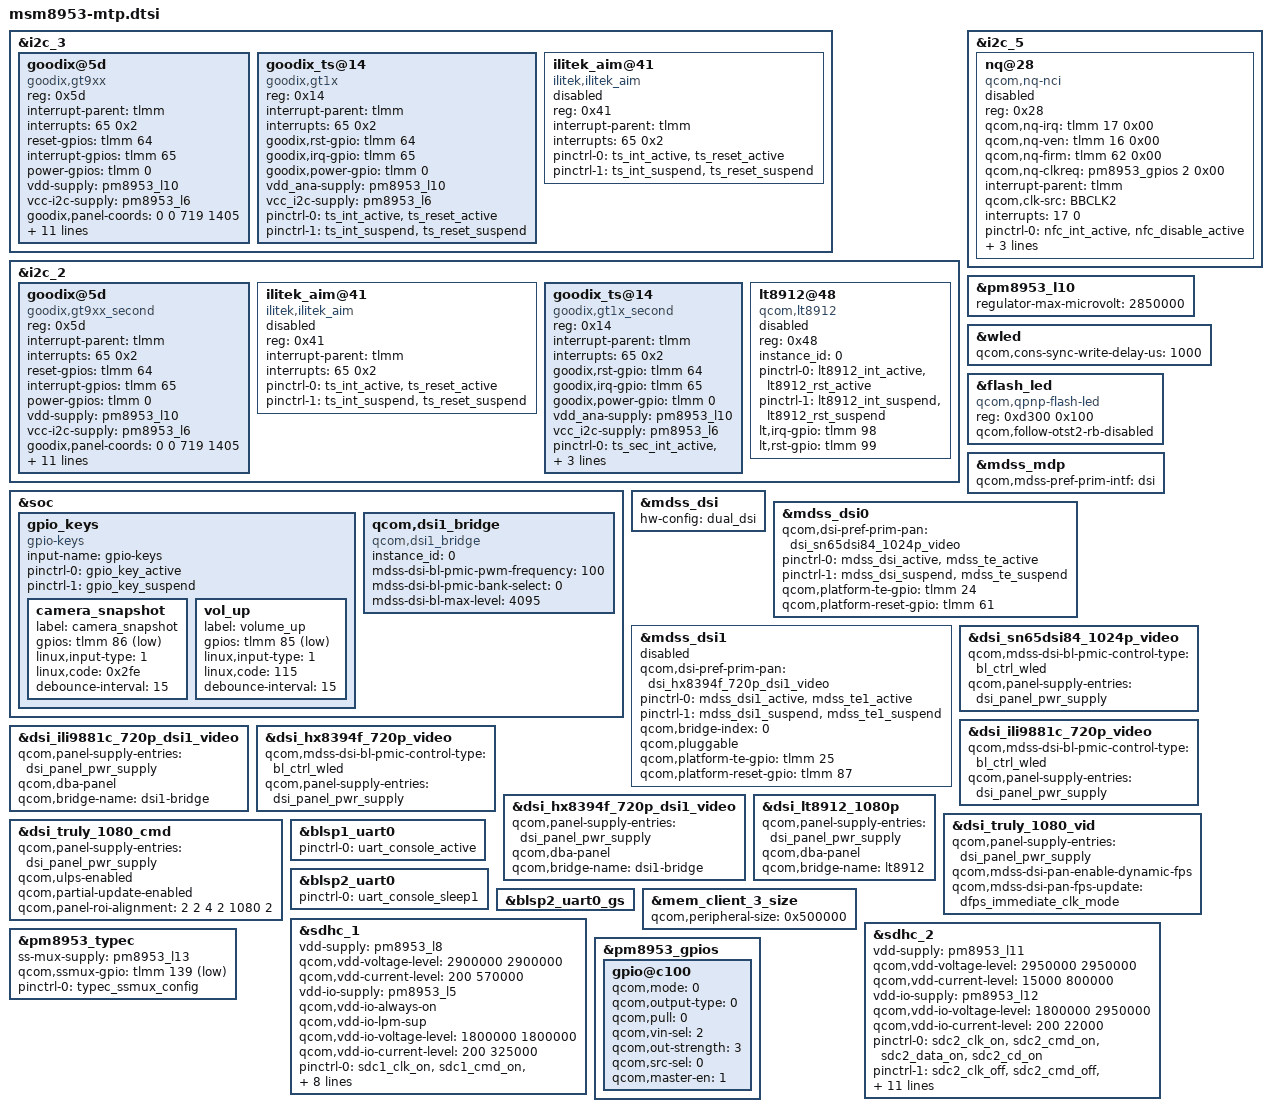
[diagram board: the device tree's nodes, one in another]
/*
 * Copyright (c) 2015-2017, The Linux Foundation. All rights reserved.
 *
 * This program is free software; you can redistribute it and/or modify
 * it under the terms of the GNU General Public License version 2 and
 * only version 2 as published by the Free Software Foundation.
 *
 * This program is distributed in the hope that it will be useful,
 * but WITHOUT ANY WARRANTY; without even the implied warranty of
 * MERCHANTABILITY or FITNESS FOR A PARTICULAR PURPOSE.  See the
 * GNU General Public License for more details.
 */

#include "msm8953-pinctrl.dtsi"
#include "msm8953-audio-mtp.dtsi"
//barnett-> del spi3
//&spi_3 { /* BLSP1 QUP3 */
/*	spi-max-frequency = <16000000>;
	maxim_sti@0 {
		status = "disabled";
		compatible = "maxim,maxim_sti";
		reg = <0>;
		interrupt-parent = <&tlmm>;
		interrupts = <65 0>;
		spi-max-frequency = <16000000>;
		avdd-supply = <&pm8953_l10>;
		dvdd-supply = <&pm8953_l5>;
		maxim_sti,irq-gpio = <&tlmm 65 0x00>;
		maxim_sti,reset-gpio = <&tlmm 64 0x00>;
		maxim_sti,touch_fusion = "/vendor/bin/touch_fusion";
		maxim_sti,config_file = "/etc/firmware/qtc800s.cfg";
		maxim_sti,fw_name = "qtc800s.bin";
		pinctrl-names = "pmx_ts_active","pmx_ts_suspend",
						"pmx_ts_release";
		pinctrl-0 = <&ts_int_active &ts_reset_active>;
		pinctrl-1 = <&ts_int_suspend &ts_reset_suspend>;
		pinctrl-2 = <&ts_release>;
	};
};
->barnett */

//barnett-> add i2c3 and gt9xx
&i2c_3 {  /* BLSP1 QUP3 */ 
    status = "ok";
    goodix@5d {
        compatible = "goodix,gt9xx";
        reg = <0x5d>;
        interrupt-parent = <&tlmm>;
        interrupts = <65 0x2>;
        reset-gpios = <&tlmm 64 0x0>;
        interrupt-gpios = <&tlmm 65 0x2008>;
        power-gpios = <&tlmm 0 0x0>;
        vdd-supply = <&pm8953_l10>;
        vcc-i2c-supply = <&pm8953_l6>;
        goodix,panel-coords = <0 0 719 1405>;
        goodix,display-coords = <0 0 719 1279>;
        goodix,button-map= <139 172 158>;
        goodix,enable-power-off;
        goodix,product-id = "9147";
        goodix,fw_name = "gtp_fw.bin";
        pinctrl-names = "pmx_ts_active","pmx_ts_suspend";
        pinctrl-0 = <&ts_int_active &ts_reset_active>;
        pinctrl-1 = <&ts_int_suspend &ts_reset_suspend>;
        goodix,cfg-data0 = [
        44 DA 02 05 05 05 35 C1 01 09
        28 08 48 35 03 05 00 00 FF 7F
        10 50 85 14 17 1A 14 92 00 0A
        31 2F D3 07 03 00 00 A2 33 1D
        00 01 00 00 00 1E 00 09 10 00
        2A 1E 50 94 C5 02 00 0E 00 04
        B1 21 00 96 28 00 7F 31 00 6F
        3B 00 60 48 00 60 10 30 48 00
        F0 4A 3A FF EF 27 00 00 00 00
        00 01 1C 19 17 0F 01 00 01 0F
        0F 03 04 10 42 8F 0F 19 00 00
        46 37 08 0A 0C 0E 10 12 14 16
        18 1A 00 00 00 00 00 00 00 00
        00 00 00 00 00 00 00 00 00 00
        00 00 08 20 0A 1F 0C 1E 0E 1D
        22 05 24 04 28 00 29 02 2A 06
        00 00 00 00 00 00 00 00 00 00
        00 FF FF FF FF FF FF FF FF AF
        FF FF FF FF 87 01
        ];
        goodix,have-touch-key;
        goodix,driver-send-cfg;
    };

    goodix_ts@14 {
		compatible = "goodix,gt1x";
		reg = <0x14>;
		interrupt-parent = <&tlmm>;
		interrupts = <65 0x2>;
		goodix,rst-gpio  = <&tlmm 64 0x0>;
		goodix,irq-gpio = <&tlmm 65 0x2008>;
		goodix,power-gpio = <&tlmm 0 0x0>;
		vdd_ana-supply = <&pm8953_l10>;
		vcc_i2c-supply  = <&pm8953_l6>;
		pinctrl-names = "pmx_ts_active","pmx_ts_suspend";
		pinctrl-0 = <&ts_int_active &ts_reset_active>;
		pinctrl-1 = <&ts_int_suspend &ts_reset_suspend>;
	};

	ilitek_aim@41 {
		compatible = "ilitek,ilitek_aim";
		reg = <0x41>;
		interrupt-parent = <&tlmm>;
		interrupts = <65 0x2>;
		pinctrl-names = "pmx_ts_active","pmx_ts_suspend";
		pinctrl-0 = <&ts_int_active &ts_reset_active>;
		pinctrl-1 = <&ts_int_suspend &ts_reset_suspend>;
		status = "disabled";
	};
};
//->barnett
//barnett-> add second tp
&i2c_2 {
    goodix@5d {
        compatible = "goodix,gt9xx_second";
        reg = <0x5d>;
        interrupt-parent = <&tlmm>;
        interrupts = <65 0x2>;
        reset-gpios = <&tlmm 64 0x0>;
        interrupt-gpios = <&tlmm 65 0x2008>;
        power-gpios = <&tlmm 0 0x0>;
        vdd-supply = <&pm8953_l10>;
        vcc-i2c-supply = <&pm8953_l6>;
        goodix,panel-coords = <0 0 719 1405>;
        goodix,display-coords = <0 0 719 1279>;
        goodix,button-map= <139 172 158>;
        goodix,enable-power-off;
        goodix,product-id = "9147";
        goodix,fw_name = "gtp_fw.bin";
        pinctrl-names = "pmx_ts_sec_active","pmx_ts_sec_suspend";
        pinctrl-0 = <&ts_int_active &ts_reset_active>;
        pinctrl-1 = <&ts_int_suspend &ts_reset_suspend>;
        goodix,cfg-data0 = [
        44 DA 02 05 05 05 35 C1 01 09
        28 08 48 35 03 05 00 00 FF 7F
        10 50 85 14 17 1A 14 92 00 0A
        31 2F D3 07 03 00 00 A2 33 1D
        00 01 00 00 00 1E 00 09 10 00
        2A 1E 50 94 C5 02 00 0E 00 04
        B1 21 00 96 28 00 7F 31 00 6F
        3B 00 60 48 00 60 10 30 48 00
        F0 4A 3A FF EF 27 00 00 00 00
        00 01 1C 19 17 0F 01 00 01 0F
        0F 03 04 10 42 8F 0F 19 00 00
        46 37 08 0A 0C 0E 10 12 14 16
        18 1A 00 00 00 00 00 00 00 00
        00 00 00 00 00 00 00 00 00 00
        00 00 08 20 0A 1F 0C 1E 0E 1D
        22 05 24 04 28 00 29 02 2A 06
        00 00 00 00 00 00 00 00 00 00
        00 FF FF FF FF FF FF FF FF AF
        FF FF FF FF 87 01
        ];
        goodix,have-touch-key;
        goodix,driver-send-cfg;
    };

	ilitek_aim@41 {
		compatible = "ilitek,ilitek_aim";
		reg = <0x41>;
		interrupt-parent = <&tlmm>;
		interrupts = <65 0x2>;
	        pinctrl-names = "pmx_ts_sec_active","pmx_ts_sec_suspend";
        	pinctrl-0 = <&ts_int_active &ts_reset_active>;
            	pinctrl-1 = <&ts_int_suspend &ts_reset_suspend>;
		status = "disabled";
	};

	goodix_ts@14 {
            compatible = "goodix,gt1x_second";
            reg = <0x14>;
            interrupt-parent = <&tlmm>;
            interrupts = <65 0x2>;
            goodix,rst-gpio  = <&tlmm 64 0x0>;
            goodix,irq-gpio = <&tlmm 65 0x2008>;
            goodix,power-gpio = <&tlmm 0 0x0>;
            vdd_ana-supply = <&pm8953_l10>;
            vcc_i2c-supply  = <&pm8953_l6>;
            pinctrl-names = "pmx_ts_sec_active","pmx_ts_sec_suspend";
            pinctrl-0 = <&ts_sec_int_active &ts_sec_reset_active>;
            pinctrl-1 = <&ts_sec_int_suspend &ts_sec_reset_suspend>;
	};
 	
     lt8912@48 {
	status = "disabled";
        compatible = "qcom,lt8912";
        reg = <0x48>;
        instance_id = <0>;
        //lt,enable-audio;
        pinctrl-names = "pmx_lt8912_active",
                       "pmx_lt8912_suspend";
        pinctrl-0 = <&lt8912_int_active &lt8912_rst_active>;
        pinctrl-1 = <&lt8912_int_suspend &lt8912_rst_suspend>;
        lt,irq-gpio = <&tlmm 98 0x2002>;
        lt,rst-gpio = <&tlmm 99 0x2002>;
    };
 };
//->barnett

&i2c_5 { /* BLSP2 QUP1 (NFC) */
	nq@28 {
		compatible = "qcom,nq-nci";
		reg = <0x28>;
		qcom,nq-irq = <&tlmm 17 0x00>;
		qcom,nq-ven = <&tlmm 16 0x00>;
		qcom,nq-firm = <&tlmm 62 0x00>;
		qcom,nq-clkreq = <&pm8953_gpios 2 0x00>;
		interrupt-parent = <&tlmm>;
		qcom,clk-src = "BBCLK2";
		interrupts = <17 0>;
		interrupt-names = "nfc_irq";
		pinctrl-names = "nfc_active", "nfc_suspend";
		pinctrl-0 = <&nfc_int_active &nfc_disable_active>;
		pinctrl-1 = <&nfc_int_suspend &nfc_disable_suspend>;
		clocks = <&clock_gcc clk_bb_clk2_pin>;
		clock-names = "ref_clk";
		status = "disabled";
	};
};

&pm8953_l10 {
	regulator-max-microvolt = <2850000>;
};

&soc {
	gpio_keys {
		compatible = "gpio-keys";
		input-name = "gpio-keys";
		pinctrl-names = "tlmm_gpio_key_active","tlmm_gpio_key_suspend";
		pinctrl-0 = <&gpio_key_active>;
		pinctrl-1 = <&gpio_key_suspend>;

		camera_snapshot {
			label = "camera_snapshot";
			gpios = <&tlmm 86 0x1>;
			linux,input-type = <1>;
			linux,code = <0x2fe>;
			debounce-interval = <15>;
		};

		vol_up {
			label = "volume_up";
			gpios = <&tlmm 85 0x1>;
			linux,input-type = <1>;
			linux,code = <115>;
			debounce-interval = <15>;
		};
	};
/*barnett-> rm improvetouch
	hbtp {
		compatible = "qcom,hbtp-input";
		vcc_ana-supply = <&pm8953_l10>;
		vcc_dig-supply = <&pm8953_l5>;
		qcom,afe-load = <50000>;
		qcom,afe-vtg-min = <2850000>;
		qcom,afe-vtg-max = <2850000>;
		qcom,dig-load = <15000>;
		qcom,dig-vtg-min = <1800000>;
		qcom,dig-vtg-max = <1800000>;
	};
->barnett*/
//barnett:add dsi1 bridge for dual mipi dsi
    qcom,dsi1_bridge {
        compatible = "qcom,dsi1_bridge";
        instance_id = <0>;
        mdss-dsi-bl-pmic-pwm-frequency = <100>;
        mdss-dsi-bl-pmic-bank-select = <0>;
        mdss-dsi-bl-max-level = <4095>;
    };
};
/*
&pmi_haptic{
	qcom,actuator-type = "lra";
	qcom,lra-auto-res-mode="qwd";
	qcom,lra-high-z="opt1";
	qcom,lra-res-cal-period = <0>;
	qcom,wave-play-rate-us = <4165>;
};
*/
&wled {
	qcom,cons-sync-write-delay-us = <1000>;
};

&flash_led {
	compatible = "qcom,qpnp-flash-led";
	reg = <0xd300 0x100>;
	qcom,follow-otst2-rb-disabled;
};

#include "msm8953-mdss-panels.dtsi"

&mdss_mdp {
	qcom,mdss-pref-prim-intf = "dsi";
};

&mdss_dsi {
	hw-config = "dual_dsi"; //"single_dsi";
};

&mdss_dsi0 {
	qcom,dsi-pref-prim-pan = <&dsi_sn65dsi84_1024p_video>;
	pinctrl-names = "mdss_default", "mdss_sleep";
	pinctrl-0 = <&mdss_dsi_active &mdss_te_active>;
	pinctrl-1 = <&mdss_dsi_suspend &mdss_te_suspend>;

	qcom,platform-te-gpio = <&tlmm 24 0>;
	qcom,platform-reset-gpio = <&tlmm 61 0>;
//	qcom,platform-bklight-en-gpio = <&tlmm 59 0>; //not use
};

&mdss_dsi1 {
	status = "disabled";
	qcom,dsi-pref-prim-pan = <&dsi_hx8394f_720p_dsi1_video>;
	pinctrl-names = "mdss_default", "mdss_sleep";
	pinctrl-0 = <&mdss_dsi1_active &mdss_te1_active>;
	pinctrl-1 = <&mdss_dsi1_suspend &mdss_te1_suspend>;

	qcom,bridge-index = <0>;
	qcom,pluggable;
	qcom,platform-te-gpio = <&tlmm 25 0>;
	qcom,platform-reset-gpio = <&tlmm 87 0>;
//	qcom,platform-bklight-en-gpio = <&tlmm 59 0>; //not use
};

&dsi_sn65dsi84_1024p_video {
        qcom,mdss-dsi-bl-pmic-control-type = "bl_ctrl_wled";
        qcom,panel-supply-entries = <&dsi_panel_pwr_supply>;
};

&dsi_ili9881c_720p_video {
	qcom,mdss-dsi-bl-pmic-control-type = "bl_ctrl_wled";
	qcom,panel-supply-entries = <&dsi_panel_pwr_supply>;
	//qcom,mdss-dsi-pan-enable-dynamic-fps;
	//qcom,mdss-dsi-pan-fps-update = "dfps_immediate_porch_mode_vfp";
	//qcom,cont-splash-enabled;
};

/*barnett: backlight control by pwm*/
&dsi_ili9881c_720p_dsi1_video {
    qcom,panel-supply-entries = <&dsi_panel_pwr_supply>;
    //qcom,mdss-dsi-pan-enable-dynamic-fps;
    //qcom,mdss-dsi-pan-fps-update = "dfps_immediate_porch_mode_vfp";
    //qcom,cont-splash-enabled;

    qcom,dba-panel;
    qcom,bridge-name = "dsi1-bridge";
};

&dsi_hx8394f_720p_video {
	qcom,mdss-dsi-bl-pmic-control-type = "bl_ctrl_wled";
	qcom,panel-supply-entries = <&dsi_panel_pwr_supply>;
	//qcom,mdss-dsi-pan-enable-dynamic-fps;
	//qcom,mdss-dsi-pan-fps-update = "dfps_immediate_porch_mode_vfp";
	//qcom,cont-splash-enabled;
};

/*barnett: backlight control by pwm*/
&dsi_hx8394f_720p_dsi1_video {
	qcom,panel-supply-entries = <&dsi_panel_pwr_supply>;
	//qcom,mdss-dsi-pan-enable-dynamic-fps;
	//qcom,mdss-dsi-pan-fps-update = "dfps_immediate_porch_mode_vfp";
	//qcom,cont-splash-enabled;

	qcom,dba-panel;
	qcom,bridge-name = "dsi1-bridge";
};

&dsi_lt8912_1080p {
    qcom,panel-supply-entries = <&dsi_panel_pwr_supply>;
    qcom,dba-panel;
    qcom,bridge-name = "lt8912";
};

&dsi_truly_1080_vid {
	qcom,panel-supply-entries = <&dsi_panel_pwr_supply>;
	qcom,mdss-dsi-pan-enable-dynamic-fps;
	qcom,mdss-dsi-pan-fps-update = "dfps_immediate_clk_mode";
};

&dsi_truly_1080_cmd {
	qcom,panel-supply-entries = <&dsi_panel_pwr_supply>;
	qcom,ulps-enabled;
	qcom,partial-update-enabled;
	qcom,panel-roi-alignment = <2 2 4 2 1080 2>;
};

&blsp1_uart0 {
	status = "ok";
	pinctrl-names = "default";
	pinctrl-0 = <&uart_console_active>;
};

&blsp2_uart0 {
	status = "ok";
	pinctrl-names = "default";
	pinctrl-0 = <&uart_console_sleep1>;
};
&blsp2_uart0_gs {
	status = "ok";
};
&mem_client_3_size {
	qcom,peripheral-size = <0x500000>;
};

&sdhc_1 {
	/* device core power supply */
	vdd-supply = <&pm8953_l8>;
	qcom,vdd-voltage-level = <2900000 2900000>;
	qcom,vdd-current-level = <200 570000>;

	/* device communication power supply */
	vdd-io-supply = <&pm8953_l5>;
	qcom,vdd-io-always-on;
	qcom,vdd-io-lpm-sup;
	qcom,vdd-io-voltage-level = <1800000 1800000>;
	qcom,vdd-io-current-level = <200 325000>;

	pinctrl-names = "active", "sleep";
	pinctrl-0 = <&sdc1_clk_on &sdc1_cmd_on &sdc1_data_on  &sdc1_rclk_on>;
	pinctrl-1 = <&sdc1_clk_off &sdc1_cmd_off &sdc1_data_off &sdc1_rclk_off>;

	qcom,clk-rates = <400000 20000000 25000000 50000000 100000000 192000000
								384000000>;
	qcom,nonremovable;
	qcom,bus-speed-mode = "HS400_1p8v", "HS200_1p8v", "DDR_1p8v";

	status = "ok";
};

&sdhc_2 {
	/* device core power supply */
	vdd-supply = <&pm8953_l11>;
	qcom,vdd-voltage-level = <2950000 2950000>;
	qcom,vdd-current-level = <15000 800000>;

	/* device communication power supply */
	vdd-io-supply = <&pm8953_l12>;
	qcom,vdd-io-voltage-level = <1800000 2950000>;
	qcom,vdd-io-current-level = <200 22000>;

	pinctrl-names = "active", "sleep";
	pinctrl-0 = <&sdc2_clk_on &sdc2_cmd_on &sdc2_data_on &sdc2_cd_on>;
	pinctrl-1 = <&sdc2_clk_off &sdc2_cmd_off &sdc2_data_off>;

	#address-cells = <0>;
	interrupt-parent = <&sdhc_2>;
	interrupts = <0 1 2>;
	#interrupt-cells = <1>;
	interrupt-map-mask = <0xffffffff>;
	interrupt-map = <0 &intc 0 125 0
		1 &intc 0 221 0
		2 &tlmm 133 0>;
	interrupt-names = "hc_irq", "pwr_irq", "status_irq";
	cd-gpios = <&tlmm 133 0x1>;

	qcom,clk-rates = <400000 20000000 25000000 50000000>;
	qcom,bus-speed-mode = "SDR12", "SDR25", "SDR50", "DDR50", "SDR104";

	status = "ok";
};

&pm8953_typec {
	ss-mux-supply = <&pm8953_l13>;
	qcom,ssmux-gpio = <&tlmm 139 GPIO_ACTIVE_LOW>;
	pinctrl-names = "default";
	pinctrl-0 = <&typec_ssmux_config>;
};

&pm8953_gpios {
	/* GPIO 2 (NFC_CLK_REQ) */
	gpio@c100 {
		qcom,mode = <0>;
		qcom,output-type = <0>;
		qcom,pull = <0>;
		qcom,vin-sel = <2>;
		qcom,out-strength = <3>;
		qcom,src-sel = <0>;
		qcom,master-en = <1>;
		status = "okay";
	};
};
